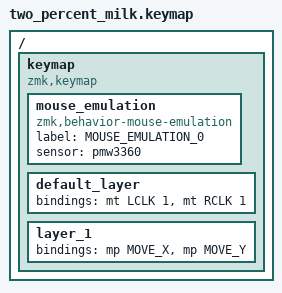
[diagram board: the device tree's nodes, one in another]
#include <dt-bindings/zmk/keys.h>
#include <dt-bindings/zmk/hid_usage.h>
#include <dt-bindings/zmk/hid_usage_pages.h>
#include <dt-bindings/zmk/mouse.h>

/ {
    keymap {
        compatible = "zmk,keymap";

        mouse_emulation {
            compatible = "zmk,behavior-mouse-emulation";
            label = "MOUSE_EMULATION_0";
            // Link this behavior to the PMW3360 node from your .overlay
            sensor = <&pmw3360>;
        };

        default_layer {
            bindings = <
                // Left key: Left click on tap, and switches to mouse layer on hold
                &mt LCLK 1 
                // Right key: Right click on tap, and switches to mouse layer on hold
                &mt RCLK 1
            >;
        };

        // This is the new mouse layer
        layer_1 {
            bindings = <
                // Left key: Left click on tap
                &mp MOVE_X
                // Right key: Right click on tap
                &mp MOVE_Y
            >;
        };
    };
};
